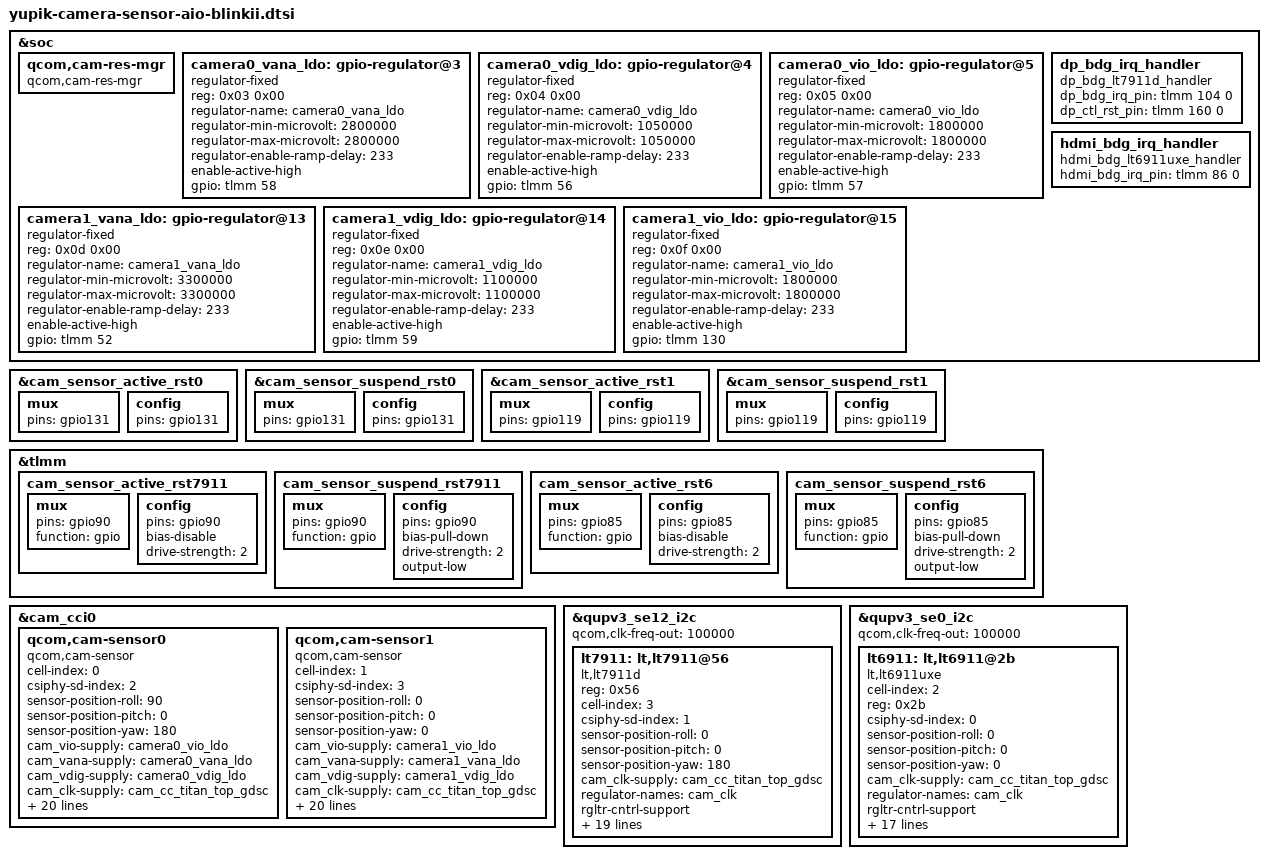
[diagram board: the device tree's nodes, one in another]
// SPDX-License-Identifier: BSD-3-Clause
/*
 * Copyright (c) Qualcomm Technologies, Inc. and/or its subsidiaries.
 */
#include <dt-bindings/msm-camera.h>

&soc {
	qcom,cam-res-mgr {
		compatible = "qcom,cam-res-mgr";
		status = "ok";
	};

	camera0_vana_ldo: gpio-regulator@3 {
		compatible = "regulator-fixed";
		reg = <0x03 0x00>;
		regulator-name = "camera0_vana_ldo";
		regulator-min-microvolt = <2800000>;
		regulator-max-microvolt = <2800000>;
		regulator-enable-ramp-delay = <233>;
		enable-active-high;
		gpio = <&tlmm 58 0>;
	};

	camera0_vdig_ldo: gpio-regulator@4 {
		compatible = "regulator-fixed";
		reg = <0x04 0x00>;
		regulator-name = "camera0_vdig_ldo";
		regulator-min-microvolt = <1050000>;
		regulator-max-microvolt = <1050000>;
		regulator-enable-ramp-delay = <233>;
		enable-active-high;
		gpio = <&tlmm 56 0>;
	};

	camera0_vio_ldo: gpio-regulator@5 {
		compatible = "regulator-fixed";
		reg = <0x05 0x00>;
		regulator-name = "camera0_vio_ldo";
		regulator-min-microvolt = <1800000>;
		regulator-max-microvolt = <1800000>;
		regulator-enable-ramp-delay = <233>;
		enable-active-high;
		gpio = <&tlmm 57 0>;
	};

	camera1_vana_ldo: gpio-regulator@13 {
		compatible = "regulator-fixed";
		reg = <0x0d 0x00>;
		regulator-name = "camera1_vana_ldo";
		regulator-min-microvolt = <3300000>;
		regulator-max-microvolt = <3300000>;
		regulator-enable-ramp-delay = <233>;
		enable-active-high;
		gpio = <&tlmm 52 0>;
	};

	camera1_vdig_ldo: gpio-regulator@14 {
		compatible = "regulator-fixed";
		reg = <0x0e 0x00>;
		regulator-name = "camera1_vdig_ldo";
		regulator-min-microvolt = <1100000>;
		regulator-max-microvolt = <1100000>;
		regulator-enable-ramp-delay = <233>;
		enable-active-high;
		gpio = <&tlmm 59 0>;
	};

	camera1_vio_ldo: gpio-regulator@15 {
		compatible = "regulator-fixed";
		reg = <0x0f 0x00>;
		regulator-name = "camera1_vio_ldo";
		regulator-min-microvolt = <1800000>;
		regulator-max-microvolt = <1800000>;
		regulator-enable-ramp-delay = <233>;
		enable-active-high;
		gpio = <&tlmm 130 0>;
	};
};

&cam_sensor_active_rst0 {
	mux {
		pins = "gpio131";
	};

	config {
		pins = "gpio131";
	};
};

&cam_sensor_suspend_rst0 {
	mux {
		pins = "gpio131";
	};

	config {
		pins = "gpio131";
	};
};

&cam_sensor_active_rst1 {
	mux {
		pins = "gpio119";
	};

	config {
		pins = "gpio119";
	};
};

&cam_sensor_suspend_rst1 {
	mux {
		pins = "gpio119";
	};

	config {
		pins = "gpio119";
	};
};

&tlmm {
		cam_sensor_active_rst7911: cam_sensor_active_rst7911 {
			/* RESET 7911 */
			mux {
				pins = "gpio90";
				function = "gpio";
			};

			config {
				pins = "gpio90";
				bias-disable; /* No PULL */
				drive-strength = <2>; /* 2 MA */
			};
		};

		cam_sensor_suspend_rst7911: cam_sensor_suspend_rst7911 {
			/* RESET 7911 */
			mux {
				pins = "gpio90";
				function = "gpio";
			};

			config {
				pins = "gpio90";
				bias-pull-down; /* PULL DOWN */
				drive-strength = <2>; /* 2 MA */
				output-low;
			};
		};

		cam_sensor_active_rst6: cam_sensor_active_rst6 {
			/* RESET 6 */
			mux {
				pins = "gpio85";
				function = "gpio";
			};

			config {
				pins = "gpio85";
				bias-disable; /* No PULL */
				drive-strength = <2>; /* 2 MA */
			};
		};

		cam_sensor_suspend_rst6: cam_sensor_suspend_rst6 {
			/* RESET 6 */
			mux {
				pins = "gpio85";
				function = "gpio";
			};

			config {
				pins = "gpio85";
				bias-pull-down; /* PULL DOWN */
				drive-strength = <2>; /* 2 MA */
				output-low;
			};
		};
};

&cam_cci0 {
	/* Wide Camera */
	qcom,cam-sensor0 {
		cell-index = <0>;
		compatible = "qcom,cam-sensor";
		csiphy-sd-index = <2>;
		sensor-position-roll = <90>;
		sensor-position-pitch = <0>;
		sensor-position-yaw = <180>;
		cam_vio-supply = <&camera0_vio_ldo>;
		cam_vana-supply = <&camera0_vana_ldo>;
		cam_vdig-supply = <&camera0_vdig_ldo>;
		cam_clk-supply = <&cam_cc_titan_top_gdsc>;
		regulator-names = "cam_vio", "cam_vana", "cam_vdig", "cam_clk";
		rgltr-cntrl-support;
		rgltr-min-voltage = <1800000 2800000 1050000 0>;
		rgltr-max-voltage = <1800000 2800000 1050000 0>;
		rgltr-load-current = <120000 80000 1200000 0>;
		gpio-no-mux = <0>;
		pinctrl-names = "cam_default", "cam_suspend";
		pinctrl-0 = <&cam_sensor_mclk2_active
				 &cam_sensor_active_rst0>;
		pinctrl-1 = <&cam_sensor_mclk2_suspend
				 &cam_sensor_suspend_rst0>;
		gpios = <&tlmm 66 0>,
			<&tlmm 131 0>;
		gpio-reset = <1>;
		gpio-req-tbl-num = <0 1>;
		gpio-req-tbl-flags = <1 0>;
		gpio-req-tbl-label = "CAMIF_MCLK2",
					"CAM_RESET3";
		cci-master = <0>;
		status = "ok";
		clocks = <&camcc CAM_CC_MCLK2_CLK>;
		clock-names = "cam_clk";
		clock-cntl-level = "nominal";
		clock-rates = <24000000>;
	};

	/* Tele camera */
	qcom,cam-sensor1 {
		cell-index = <1>;
		compatible = "qcom,cam-sensor";
		csiphy-sd-index = <3>;
		sensor-position-roll = <0>;
		sensor-position-pitch = <0>;
		sensor-position-yaw = <0>;
		cam_vio-supply = <&camera1_vio_ldo>;
		cam_vana-supply = <&camera1_vana_ldo>;
		cam_vdig-supply = <&camera1_vdig_ldo>;
		cam_clk-supply = <&cam_cc_titan_top_gdsc>;
		regulator-names = "cam_vio", "cam_vana", "cam_vdig", "cam_clk";
		rgltr-cntrl-support;
		rgltr-min-voltage = <1800000 3300000 1100000 0>;
		rgltr-max-voltage = <1800000 3300000 1100000 0>;
		rgltr-load-current = <120000 80000 1200000 0>;
		gpio-no-mux = <0>;
		pinctrl-names = "cam_default", "cam_suspend";
		pinctrl-0 = <&cam_sensor_mclk1_active
				 &cam_sensor_active_rst1>;
		pinctrl-1 = <&cam_sensor_mclk1_suspend
				 &cam_sensor_suspend_rst1>;
		gpios = <&tlmm 65 0>,
			<&tlmm 119 0>;
		gpio-reset = <1>;
		gpio-req-tbl-num = <0 1>;
		gpio-req-tbl-flags = <1 0>;
		gpio-req-tbl-label = "CAMIF_MCLK1",
					"CAM_RESET4";
		cci-master = <1>;
		status = "ok";
		clocks = <&camcc CAM_CC_MCLK1_CLK>;
		clock-names = "cam_clk";
		clock-cntl-level = "nominal";
		clock-rates = <24000000>;
	};
};

/*lt7911d-dp*/
&qupv3_se12_i2c {
	status = "ok";
	qcom,clk-freq-out = <100000>;
	lt7911: lt,lt7911@56 {
		compatible = "lt,lt7911d";
		reg = <0x56>;
		cell-index = <3>;
		csiphy-sd-index = <1>;
		sensor-position-roll = <0>;
		sensor-position-pitch = <0>;
		sensor-position-yaw = <180>;
		cam_clk-supply = <&cam_cc_titan_top_gdsc>;
		regulator-names = "cam_clk";
		rgltr-cntrl-support;
		pwm-switch;
		rgltr-min-voltage = <0>;
		rgltr-max-voltage = <0>;
		rgltr-load-current = <0>;
		gpio-no-mux = <0>;
		pinctrl-names = "cam_default", "cam_suspend";
		pinctrl-0 = <&cam_sensor_active_rst7911>;
		pinctrl-1 = <&cam_sensor_suspend_rst7911>;
		gpios = <&tlmm 90 0>,
			<&tlmm 95 0>,
			<&tlmm 94 0>;
		gpio-reset = <0>;
		gpio-custom1 = <1>;
		gpio-custom2 = <2>;
		gpio-req-tbl-num = <0 1 2>;
		gpio-req-tbl-flags = <0 0 0>;
		gpio-req-tbl-label = "CAM_RESET1", "DP_ENABLE_1", "DP_ENABLE_2";
		sensor-mode = <0>;
		clocks = <&camcc CAM_CC_MCLK3_CLK>;
		clock-names = "cam_clk";
		clock-cntl-level = "turbo";
		clock-rates = <24000000>;

		status = "ok";
	};
};

/*lt6911uxe-hdmi*/
&qupv3_se0_i2c {
	status = "ok";
	qcom,clk-freq-out = <100000>;
	lt6911: lt,lt6911@2b {
		cell-index = <2>;
		compatible = "lt,lt6911uxe";
		reg = <0x2b>;
		csiphy-sd-index = <0>;
		sensor-position-roll = <0>;
		sensor-position-pitch = <0>;
		sensor-position-yaw = <0>;
		cam_clk-supply = <&cam_cc_titan_top_gdsc>;
		regulator-names = "cam_clk";
		rgltr-cntrl-support;
		pwm-switch;
		rgltr-min-voltage = <0>;
		rgltr-max-voltage = <0>;
		rgltr-load-current = <0>;
		pinctrl-names = "cam_default", "cam_suspend";
		pinctrl-0 = <&cam_sensor_active_rst6>;
		pinctrl-1 = <&cam_sensor_suspend_rst6>;
		gpio-no-mux = <0>;
		gpios = <&tlmm 85 0>,
			<&tlmm 84 0>;
		gpio-reset = <0>;
		gpio-custom1 = <1>;
		gpio-req-tbl-num = <0 1>;
		gpio-req-tbl-flags = <0 0>;
		gpio-req-tbl-label = "HDMI_RESET0",
				"HDMI_ENABLE_1";
		sensor-mode = <0>;
		clocks = <&camcc CAM_CC_MCLK3_CLK>;
		clock-names = "cam_clk";
		clock-cntl-level = "turbo";
		clock-rates = <24000000>;
		status = "ok";
	};
};

&soc {
	dp_bdg_irq_handler: dp_bdg_irq_handler {
		status = "ok";
		compatible = "dp_bdg_lt7911d_handler";
		dp_bdg_irq_pin = <&tlmm 104 0>;
		dp_ctl_rst_pin = <&tlmm 160 0>;
	};

        hdmi_bdg_irq_handler: hdmi_bdg_irq_handler {
                status = "ok";
                compatible = "hdmi_bdg_lt6911uxe_handler";
                hdmi_bdg_irq_pin = <&tlmm 86 0>;
        };
};

